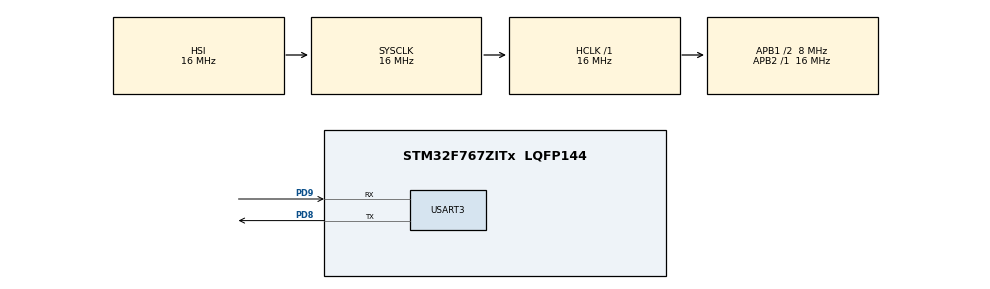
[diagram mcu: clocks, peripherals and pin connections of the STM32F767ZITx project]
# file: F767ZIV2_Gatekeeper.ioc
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Mcu.Family=STM32F7
FREERTOS.Queues01=msgQueue,16,uint16_t,0,Dynamic,NULL,NULL
RCC.CortexFreq_Value=16000000
FREERTOS.Tasks01=writerOne,24,128,writerOneHook,Default,NULL,Dynamic,NULL,NULL;writerTwo,24,128,writerTwoHook,Default,NULL,Dynamic,NULL,NULL;gateKeeper,24,128,gateKeeperHook,Default,NULL,Dynamic,NULL,NULL
RCC.SYSCLKSourceVirtual=RCC_SYSCLKSOURCE_PLLCLK
PD9.Signal=USART3_RX
RCC.APB1CLKDivider=RCC_HCLK_DIV2
PD9.Mode=Asynchronous
ProjectManager.StackSize=0x400
VP_FREERTOS_VS_CMSIS_V2.Mode=CMSIS_V2
USART3.VirtualMode-Asynchronous=VM_ASYNC
PA13.Signal=SYS_JTMS-SWDIO
ProjectManager.TargetToolchain=STM32CubeIDE
RCC.HCLKFreq_Value=16000000
RCC.APB2TimFreq_Value=16000000
PD8.Signal=USART3_TX
RCC.USBFreq_Value=96000000
RCC.LSE_VALUE=32768
PD8.Mode=Asynchronous
RCC.AHBFreq_Value=16000000
RCC.HSE_VALUE=16000000
board=NUCLEO-F767ZI
RCC.VCOOutputFreq_Value=192000000
RCC.PLLMUL=RCC_PLL_MUL9
RCC.APB2Freq_Value=16000000
RCC.PRESCALERUSB=RCC_USBCLKSOURCE_PLL_DIV1_5
PA14.Mode=Serial_Wire
VP_SYS_VS_tim1.Mode=TIM1
PA13.Mode=Serial_Wire
Mcu.Name=STM32F767ZITx
RCC.48MHZClocksFreq_Value=24000000
RCC.SYSCLKFreq_VALUE=16000000
Mcu.Package=LQFP144
NVIC.TimeBase=TIM1_UP_TIM10_IRQn
NVIC.TimeBaseIP=TIM1
PA14.Signal=SYS_JTCK-SWCLK
ProjectManager.HeapSize=0x200
NVIC.TIM1_UP_TIM10_IRQn=true\:0\:0\:false\:false\:true\:false\:false\:true
RCC.HSI_VALUE=16000000
NVIC.PriorityGroup=NVIC_PRIORITYGROUP_4
RCC.APB1TimFreq_Value=16000000
RCC.APB1Freq_Value=8000000

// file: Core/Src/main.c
/* USER CODE BEGIN Header */
/**
  ******************************************************************************
  * @file           : main.c
  * @brief          : Main program body
  ******************************************************************************
  * @attention
  *
  * <h2><center>&copy; Copyright (c) 2021 STMicroelectronics.
  * All rights reserved.</center></h2>
  *
  * This software component is licensed by ST under Ultimate Liberty license
  * SLA0044, the "License"; You may not use this file except in compliance with
  * the License. You may obtain a copy of the License at:
  *                             www.st.com/SLA0044
  *
  ******************************************************************************
  */
/* USER CODE END Header */
#include "main.h"
#include "cmsis_os.h"
#include "string.h"

UART_HandleTypeDef huart3;

/* Definitions for writerOne */
osThreadId_t writerOneHandle;
const osThreadAttr_t writerOne_attributes = {
  .name = "writerOne",
  .priority = (osPriority_t) osPriorityNormal,
  .stack_size = 128 * 4
};
/* Definitions for writerTwo */
osThreadId_t writerTwoHandle;
const osThreadAttr_t writerTwo_attributes = {
  .name = "writerTwo",
  .priority = (osPriority_t) osPriorityNormal,
  .stack_size = 128 * 4
};
/* Definitions for gateKeeper */
osThreadId_t gateKeeperHandle;
const osThreadAttr_t gateKeeper_attributes = {
  .name = "gateKeeper",
  .priority = (osPriority_t) osPriorityNormal,
  .stack_size = 128 * 4
};
/* Definitions for msgQueue */
osMessageQueueId_t msgQueueHandle;
const osMessageQueueAttr_t msgQueue_attributes = {
  .name = "msgQueue"
};

void SystemClock_Config(void);
static void MX_GPIO_Init(void);
static void MX_USART3_UART_Init(void);
void writerOneHook(void *argument);
void writerTwoHook(void *argument);
void gateKeeperHook(void *argument);

/* USER CODE BEGIN 0 */
typedef struct {
	uint8_t msg_code;
	uint8_t task_id;
} MSG_Type;
/* USER CODE END 0 */

int main(void)
{

  /* MCU Configuration--------------------------------------------------------*/

  /* Reset of all peripherals, Initializes the Flash interface and the Systick. */
  HAL_Init();

  /* Configure the system clock */
  SystemClock_Config();

  /* Initialize all configured peripherals */
  MX_GPIO_Init();
  MX_USART3_UART_Init();

  /* Init scheduler */
  osKernelInitialize();

  /* Create the queue(s) */
  /* creation of msgQueue */
  msgQueueHandle = osMessageQueueNew (16, sizeof(uint16_t), &msgQueue_attributes);

  /* Create the thread(s) */
  /* creation of writerOne */
  writerOneHandle = osThreadNew(writerOneHook, NULL, &writerOne_attributes);

  /* creation of writerTwo */
  writerTwoHandle = osThreadNew(writerTwoHook, NULL, &writerTwo_attributes);

  /* creation of gateKeeper */
  gateKeeperHandle = osThreadNew(gateKeeperHook, NULL, &gateKeeper_attributes);

  /* Start scheduler */
  osKernelStart();

  /* We should never get here as control is now taken by the scheduler */
  /* Infinite loop */
  while (1)
  {

  }
}

void SystemClock_Config(void)
{
  RCC_OscInitTypeDef RCC_OscInitStruct = {0};
  RCC_ClkInitTypeDef RCC_ClkInitStruct = {0};
  RCC_PeriphCLKInitTypeDef PeriphClkInitStruct = {0};

  /** Configure the main internal regulator output voltage
  */
  __HAL_RCC_PWR_CLK_ENABLE();
  __HAL_PWR_VOLTAGESCALING_CONFIG(PWR_REGULATOR_VOLTAGE_SCALE3);
  /** Initializes the RCC Oscillators according to the specified parameters
  * in the RCC_OscInitTypeDef structure.
  */
  RCC_OscInitStruct.OscillatorType = RCC_OSCILLATORTYPE_HSI;
  RCC_OscInitStruct.HSIState = RCC_HSI_ON;
  RCC_OscInitStruct.HSICalibrationValue = RCC_HSICALIBRATION_DEFAULT;
  RCC_OscInitStruct.PLL.PLLState = RCC_PLL_NONE;
  if (HAL_RCC_OscConfig(&RCC_OscInitStruct) != HAL_OK)
  {
    Error_Handler();
  }
  /** Initializes the CPU, AHB and APB buses clocks
  */
  RCC_ClkInitStruct.ClockType = RCC_CLOCKTYPE_HCLK|RCC_CLOCKTYPE_SYSCLK
                              |RCC_CLOCKTYPE_PCLK1|RCC_CLOCKTYPE_PCLK2;
  RCC_ClkInitStruct.SYSCLKSource = RCC_SYSCLKSOURCE_HSI;
  RCC_ClkInitStruct.AHBCLKDivider = RCC_SYSCLK_DIV1;
  RCC_ClkInitStruct.APB1CLKDivider = RCC_HCLK_DIV2;
  RCC_ClkInitStruct.APB2CLKDivider = RCC_HCLK_DIV1;

  if (HAL_RCC_ClockConfig(&RCC_ClkInitStruct, FLASH_LATENCY_0) != HAL_OK)
  {
    Error_Handler();
  }
  PeriphClkInitStruct.PeriphClockSelection = RCC_PERIPHCLK_USART3;
  PeriphClkInitStruct.Usart3ClockSelection = RCC_USART3CLKSOURCE_PCLK1;
  if (HAL_RCCEx_PeriphCLKConfig(&PeriphClkInitStruct) != HAL_OK)
  {
    Error_Handler();
  }
}

static void MX_USART3_UART_Init(void)
{

  huart3.Instance = USART3;
  huart3.Init.BaudRate = 115200;
  huart3.Init.WordLength = UART_WORDLENGTH_8B;
  huart3.Init.StopBits = UART_STOPBITS_1;
  huart3.Init.Parity = UART_PARITY_NONE;
  huart3.Init.Mode = UART_MODE_TX_RX;
  huart3.Init.HwFlowCtl = UART_HWCONTROL_NONE;
  huart3.Init.OverSampling = UART_OVERSAMPLING_16;
  huart3.Init.OneBitSampling = UART_ONE_BIT_SAMPLE_DISABLE;
  huart3.AdvancedInit.AdvFeatureInit = UART_ADVFEATURE_NO_INIT;
  if (HAL_UART_Init(&huart3) != HAL_OK)
  {
    Error_Handler();
  }

}

static void MX_GPIO_Init(void)
{

  /* GPIO Ports Clock Enable */
  __HAL_RCC_GPIOD_CLK_ENABLE();
  __HAL_RCC_GPIOA_CLK_ENABLE();

}

void writerOneHook(void *argument)
{
	MSG_Type msg;

	for(;;){
		msg.msg_code = 1;
		msg.task_id  = 1;
		osMessageQueuePut(msgQueueHandle, &msg, 0U, 0U);
		HAL_Delay(1000);
	}
}

void writerTwoHook(void *argument)
{
	MSG_Type msg;

	for(;;){
		msg.msg_code = 2;
		msg.task_id  = 2;
		osMessageQueuePut(msgQueueHandle, &msg, 0U, 0U);
		HAL_Delay(2000);
	}
}

void gateKeeperHook(void *argument)
{
	MSG_Type msg;
	osStatus_t status;
	const uint8_t * const w1_msg = "Writer 1 : -----------------------------------\r\n";
	const uint8_t * const w2_msg = "Writer 2 : ooooooooooooooooooooooooooooooooooo\r\n";

	for(;;) {
		status = osMessageQueueGet(msgQueueHandle, &msg, NULL, 0U);   // wait for message
		if (status == osOK) {
			switch(msg.msg_code){
				case 1 : HAL_UART_Transmit(&huart3, w1_msg, strlen(w1_msg), 100);
				case 2 : HAL_UART_Transmit(&huart3, w2_msg, strlen(w2_msg), 100);
			}
		}
	}
}

 /**
  * @brief  Period elapsed callback in non blocking mode
  * @note   This function is called  when TIM1 interrupt took place, inside
  * HAL_TIM_IRQHandler(). It makes a direct call to HAL_IncTick() to increment
  * a global variable "uwTick" used as application time base.
  * @param  htim : TIM handle
  * @retval None
  */
void HAL_TIM_PeriodElapsedCallback(TIM_HandleTypeDef *htim)
{
  if (htim->Instance == TIM1) {
    HAL_IncTick();
  }
}

void Error_Handler(void)
{
  __disable_irq();
  while (1)
  {
  }
}

/************************ (C) COPYRIGHT STMicroelectronics *****END OF FILE****/
